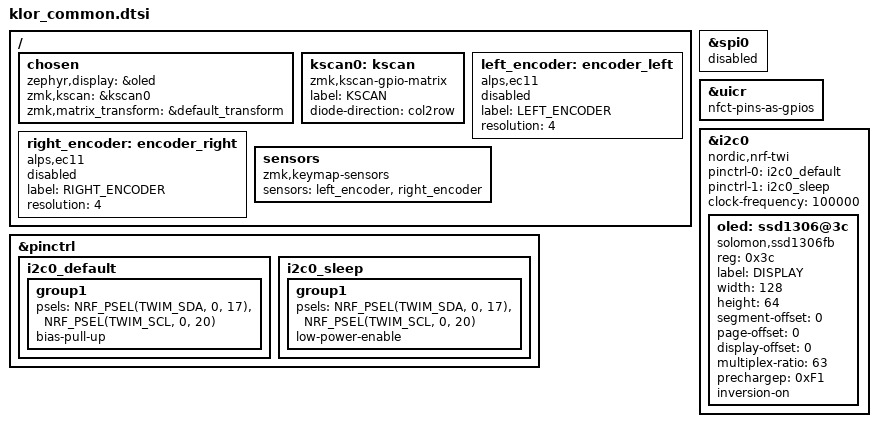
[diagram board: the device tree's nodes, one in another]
/*
 * Copyright (c) 2022 The ZMK Contributors
 *
 * SPDX-License-Identifier: MIT
 */

#include <dt-bindings/zmk/matrix_transform.h>

/ {
	chosen {
		zephyr,display = &oled;
		zmk,kscan = &kscan0;
		zmk,matrix_transform = &default_transform;
	};

	kscan0: kscan {
		compatible = "zmk,kscan-gpio-matrix";
		label = "KSCAN";

		diode-direction = "col2row";		
	};

	left_encoder: encoder_left {
		compatible = "alps,ec11";
		label = "LEFT_ENCODER";
		resolution = <4>;
		status = "disabled";
	};

	right_encoder: encoder_right {
		compatible = "alps,ec11";
		label = "RIGHT_ENCODER";
		resolution = <4>;
		status = "disabled";
	};

	sensors {
		compatible = "zmk,keymap-sensors";
		sensors = <&left_encoder &right_encoder>;
	};
};
&spi0 { status = "disabled"; };
&uicr { nfct-pins-as-gpios; };

&pinctrl {
    i2c0_default: i2c0_default {
        group1 {
            psels = <NRF_PSEL(TWIM_SDA, 0, 17)>,
                    <NRF_PSEL(TWIM_SCL, 0, 20)>;
            bias-pull-up;
        };
    };


    i2c0_sleep: i2c0_sleep {
        group1 {
            psels = <NRF_PSEL(TWIM_SDA, 0, 17)>,
                    <NRF_PSEL(TWIM_SCL, 0, 20)>;
            low-power-enable;
        };
    };
};

&i2c0 {
	status = "okay";
	compatible = "nordic,nrf-twi";
	pinctrl-0 = <&i2c0_default>;
	pinctrl-1 = <&i2c0_sleep>;
	pinctrl-names = "default", "sleep";
	/* clock-frequency = <I2C_BITRATE_STANDARD>; */
	clock-frequency = <100000>;

	oled: ssd1306@3c {
		compatible = "solomon,ssd1306fb";
		reg = <0x3c>;
		label = "DISPLAY";
		width = <128>;
		height = <64>;
		segment-offset = <0>;
		page-offset = <0>;
		display-offset = <0>;
		multiplex-ratio = <63>;
		prechargep = <0xF1>;
      		inversion-on;
	};
};
